AUTOSAR XML (schema 4-0-3)
package /ComponentTypes
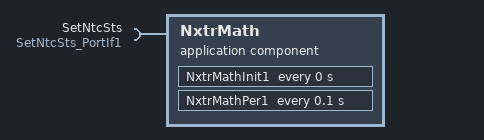
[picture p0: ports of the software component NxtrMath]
  application sw component type NxtrMath
    require port SetNtcSts: client-com-spec=Oper, required-interface=SetNtcSts_PortIf1
    behavior NxtrMath_InternalBehavior: data-type-mapping=Nexteer
      timing event NxtrMath_InitEvent: start-on-event=NxtrMathInit1, period=0
      timing event TMT_NxtrMathPer1: start-on-event=NxtrMathPer1, period=0.1
      runnable NxtrMathInit1
        sync call SC_SetNtcSts_Oper: operation=SetNtcSts.Oper, timeout=0
      runnable NxtrMathPer1
        sync call SC_SetNtcSts_Oper: operation=SetNtcSts.Oper, timeout=0
  swc implementation NxtrMath_Implementation: behavior=NxtrMath_InternalBehavior
    code-descriptors:
      code Default: artifact-descriptors=autosar-engineering-object={short-label=Default, category=SWSRC}
